# CC2753 register map
File version: 1.0
CPU: CM0+ r0p4, little endian, no MPU, no FPU, VTOR, 3 interrupt priority bits
Registers are 32-bit, read-write, reset 0x0 unless marked. A register's access mark holds for its fields unless they carry their own. Offsets are from the block's base; [hi:lo] are bit positions; {n}, {i} and the like mark numbered series.

## UART0 — Universal Asynchronous Receiver/Transmitter (UART) interface
Base 0x40034000
Same registers: UART1 0x40035000
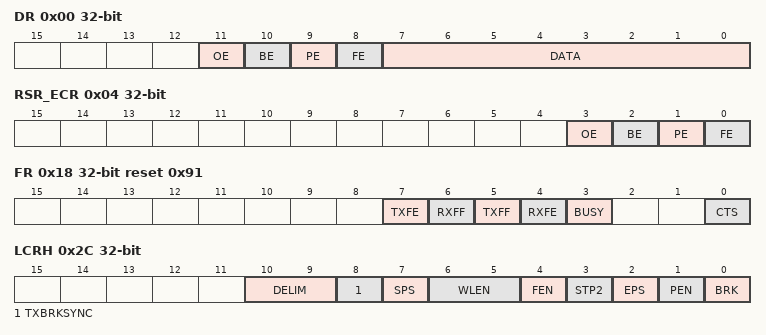
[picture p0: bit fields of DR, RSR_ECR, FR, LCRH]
0x00 DR — Data For words to be transmitted: - if the FIFOs are enabled (LCRH.FEN = 1), data written to this location is pushed onto the transmit FIFO - if the FIFOs are not enabled (LCRH.FEN = 0), data is stored in the transmitter holding register (the bottom word of the transmit FIFO). The write operation initiates transmission from the UART. The data is prefixed with a start bit, appended with the appropriate parity bit (if parity is enabled), and a stop bit. The resultant word is then transmitted. For received words: - if the FIFOs are enabled (LCRH.FEN = 1), the data byte and the 4-bit status (break, frame, parity, and overrun) is pushed onto the 12-bit wide receive FIFO - if the FIFOs are not enabled (LCRH.FEN = 0), the data byte and status are stored in the receiving holding register (the bottom word of the receive FIFO). The received data byte is read by performing reads from this register along with the corresponding status information. The status information can also be read by a read of the RSR_ECR register.
  [11] OE ro — UART Overrun Error: This bit is set to 1 if data is received and the receive FIFO is already full. The FIFO contents remain valid because no more data is written when the FIFO is full, only the contents of the shift register are overwritten. This is cleared to 0 once there is an empty space in the FIFO and a new character can be written to it.
  [10] BE ro — UART Break Error: This bit is set to 1 if a break condition was detected, indicating that the received data input (UARTRXD input pin) was held LOW for longer than a full-word transmission time (defined as start, data, parity and stop bits). In FIFO mode, this error is associated with the character at the top of the FIFO (i.e., the oldest received data character since last read). When a break occurs, a 0 character is loaded into the FIFO. The next character is enabled after the receive data input (UARTRXD input pin) goes to a 1 (marking state), and the next valid start bit is received.
  [9] PE ro — UART Parity Error: When set to 1, it indicates that the parity of the received data character does not match the parity that the LCRH.EPS and LCRH.SPS select. In FIFO mode, this error is associated with the character at the top of the FIFO (i.e., the oldest received data character since last read).
  [8] FE ro — UART Framing Error: When set to 1, it indicates that the received character did not have a valid stop bit (a valid stop bit is 1). In FIFO mode, this error is associated with the character at the top of the FIFO (i.e., the oldest received data character since last read).
  [7:0] DATA — Data transmitted or received: On writes, the transmit data character is pushed into the FIFO. On reads, the oldest received data character since the last read is returned.
0x04 RSR_ECR — Status This register is mapped to the same address as ECR register. Reads from this address are associated with RSR_ECR register and return the receive status. Writes to this address are associated with ECR register and clear the receive status flags (framing, parity, break, and overrun errors). If the status is read from this register, then the status information for break, framing and parity corresponds to the data character read from the Data Register DR, prior to reading the RSR_ECR. The status information for overrun is set immediately when an overrun condition occurs.
  [all] fields
    1=CLEAR_ERROR_1 (Clears error flag if error is set. Write value is not important.); 0=ERROR_NOTSET (Error flag is not set)
  [3] OE — UART Overrun Error: This bit is set to 1 if data is received and the receive FIFO is already full. The FIFO contents remain valid because no more data is written when the FIFO is full, only the contents of the shift register are overwritten. This is cleared to 0 once there is an empty space in the FIFO and a new character can be written to it.
  [2] BE — UART Break Error: This bit is set to 1 if a break condition was detected, indicating that the received data input (UARTRXD input pin) was held LOW for longer than a full-word transmission time (defined as start, data, parity and stop bits). When a break occurs, a 0 character is loaded into the FIFO. The next character is enabled after the receive data input (UARTRXD input pin) goes to a 1 (marking state), and the next valid start bit is received.
  [1] PE — UART Parity Error: When set to 1, it indicates that the parity of the received data character does not match the parity that the LCRH.EPS and LCRH.SPS select.
  [0] FE — UART Framing Error: When set to 1, it indicates that the received character did not have a valid stop bit (a valid stop bit is 1).
0x18 FR ro reset 0x91 — Flag Reads from this register return the UART flags.
  [7] TXFE — UART Transmit FIFO Empty: The meaning of this bit depends on the state of LCRH.FEN . - If the FIFO is disabled, this bit is set when the transmit holding register is empty. - If the FIFO is enabled, this bit is set when the transmit FIFO is empty. This bit does not indicate if there is data in the transmit shift register.
  [6] RXFF — UART Receive FIFO Full: The meaning of this bit depends on the state of LCRH.FEN. - If the FIFO is disabled, this bit is set when the receive holding register is full. - If the FIFO is enabled, this bit is set when the receive FIFO is full.
  [5] TXFF — UART Transmit FIFO Full: Transmit FIFO full. The meaning of this bit depends on the state of LCRH.FEN. - If the FIFO is disabled, this bit is set when the transmit holding register is full. - If the FIFO is enabled, this bit is set when the transmit FIFO is full.
  [4] RXFE — UART Receive FIFO Empty: Receive FIFO empty. The meaning of this bit depends on the state of LCRH.FEN. - If the FIFO is disabled, this bit is set when the receive holding register is empty. - If the FIFO is enabled, this bit is set when the receive FIFO is empty.
  [3] BUSY — UART Busy: If this bit is set to 1, the UART is busy transmitting data. This bit remains set until the complete byte, including all the stop bits, has been sent from the shift register. This bit is set as soon as the transmit FIFO becomes non-empty, regardless of whether the UART is enabled or not.
  [0] CTS — Clear To Send: This bit is the complement of the active-low UART CTS input pin. That is, the bit is 1 when CTS input pin is LOW.
0x20 UARTILPR — IrDA Low-Power Counter Register. This is an 8-bit register that stores the low-power counter divisor value used to generate the IrLPBaud16 signal by dividing down of UARTCLK.
  [7:0] ILPDVSR — 8 bit low-power divisor value. In low-power IrDA mode the UART rejects random noise on the received serial data input by ignoring SIRIN pulses that are less than 3 periods of IrLPBaud16.
0x24 IBRD — Integer Baud-Rate Divisor If this register is modified while trasmission or reception is on-going, the baudrate will not be updated until transmission or reception of the current character is complete.
  [15:0] DIVINT — The integer baud rate divisor: The baud rate divisor is calculated using the formula below: Baud rate divisor = (UART reference clock frequency) / (16 * Baud rate) Baud rate divisor must be minimum 1 and maximum 65535. That is, DIVINT=0 does not give a valid baud rate. Similarly, if DIVINT=0xFFFF, any non-zero values in FBRD.DIVFRAC will be illegal. A valid value must be written to this field before the UART can be used for RX or TX operations.
0x28 FBRD — Fractional Baud-Rate Divisor If this register is modified while trasmission or reception is on-going, the baudrate will not be updated until transmission or reception of the current character is complete.
  [5:0] DIVFRAC — Fractional Baud-Rate Divisor: The baud rate divisor is calculated using the formula below: Baud rate divisor = (UART reference clock frequency) / (16 * Baud rate) Baud rate divisor must be minimum 1 and maximum 65535. That is, IBRD.DIVINT=0 does not give a valid baud rate. Similarly, if IBRD.DIVINT=0xFFFF, any non-zero values in DIVFRAC will be illegal. A valid value must be written to this field before the UART can be used for RX or TX operations.
0x2C LCRH — Line Control
  [10:9] DELIM — In UART LIN defines the length of DELIM field that has to be sent
    {v}=LEN_{v+1} (v=0..3)
  [8] TXBRKSYNC — UART LIN mode TXBRKSYNC: 0: In LIN mode TXBRKSYNC will not be sent. 1: In LIN mode send TXBRKSYNC field and reset the LCRH.TXBRKSYNC bit. This bit has no effect when PEN disables parity checking and generation.
  [7] SPS — UART Stick Parity Select: 0: Stick parity is disabled 1: The parity bit is transmitted and checked as invert of EPS field (i.e. the parity bit is transmitted and checked as 1 when EPS = 0). This bit has no effect when PEN disables parity checking and generation.
  [6:5] WLEN — UART Word Length: These bits indicate the number of data bits transmitted or received in a frame.
    {v}=BITL{v+5} (Word Length {v+5} bits) (v=0..3)
  [4] FEN — UART Enable FIFOs
    1=EN (Transmit and receive FIFO buffers are enabled (FIFO mode)); 0=DIS (FIFOs are disabled (character mode) that is, the FIFOs become 1-byte-deep holding registers.)
  [3] STP2 — UART Two Stop Bits Select: If this bit is set to 1, two stop bits are transmitted at the end of the frame. The receive logic does not check for two stop bits being received.
  [2] EPS — UART Even Parity Select
    1=EVEN (Even parity: The UART generates or checks for an even number of 1s in the data and parity bits.); 0=ODD (Odd parity: The UART generates or checks for an odd number of 1s in the data and parity bits.)
  [1] PEN — UART Parity Enable This bit controls generation and checking of parity bit.
    1=EN (Parity checking and generation is enabled.); 0=DIS (Parity is disabled and no parity bit is added to the data frame)
  [0] BRK — UART Send Break If this bit is set to 1, a low-level is continually output on the UARTTXD output pin, after completing transmission of the current character. For the proper execution of the break command, the software must set this bit for at least two complete frames. For normal use, this bit must be cleared to 0.
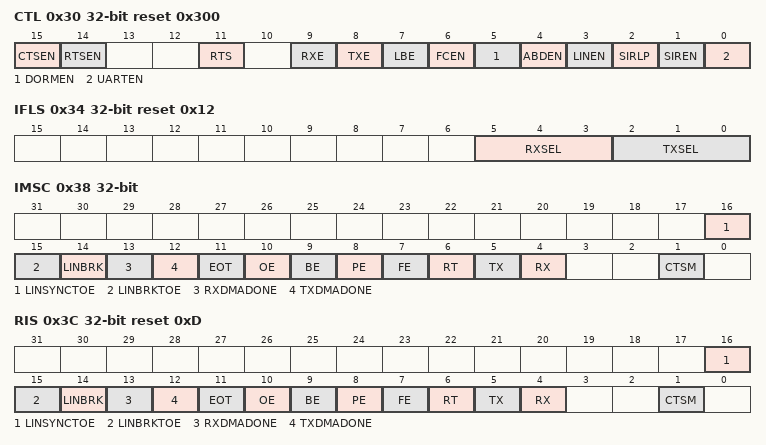
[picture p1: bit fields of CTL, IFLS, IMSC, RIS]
0x30 CTL reset 0x300 — Control
  [15] CTSEN — CTS hardware flow control enable
    1=EN (CTS hardware flow control enabled); 0=DIS (CTS hardware flow control disabled)
  [14] RTSEN — RTS hardware flow control enable
    1=EN (RTS hardware flow control enabled); 0=DIS (RTS hardware flow control disabled)
  [11] RTS — Request to Send This bit is the complement of the active-low UART RTS output. That is, when the bit is programmed to a 1 then RTS output on the pins is LOW.
  [9] RXE — UART Receive Enable If the UART is disabled in the middle of reception, it completes the current character before stopping.
    1=EN (UART Receive enabled); 0=DIS (UART Receive disabled)
  [8] TXE — UART Transmit Enable If the UART is disabled in the middle of transmission, it completes the current character before stopping.
    1=EN (UART Transmit enabled); 0=DIS (UART Transmit disabled)
  [7] LBE — UART Loop Back Enable Enabling the loop-back mode connects the UARTTXD output from the UART to UARTRXD input of the UART.
    1=EN (Loop Back enabled); 0=DIS (Loop Back disabled)
  [6] FCEN — UART FIFO Concatenation Enable Enabling the FIFO concatenation in TX mode resulting in 16 TX buffers.
    1=EN (UART FIFO Concatenation enabled); 0=DIS (UART FIFO Concatenation disabled)
  [5] DORMEN — DORMEN bit is only functionally makes sense for LIN mode of operation. When dormant mode is disabled, break and synch data shall be loaded to RX FIFO and associated interrupt flags shall be set as in normal UART operation. When dormant mode is enabled, break and synch data shall not be loaded to RX FIFO and RX FIFO shall be updated with actual data (PID) only after successful reception of break/synch fields.
    1=EN; 0=DIS
  [4] ABDEN — This configuration bit defines whether we want automatic baud rate detection enabled or not in the LIN mode of operation.
    1=EN; 0=DIS
  [3] LINEN — This is the LIN Mode of operation configuration bit.
    1=EN; 0=DIS
  [2] SIRLP — SIR low power IrDA mode This bit selects the IrDA encoding mode
    1=EN (Low-level bits are transmitted with a pulse width of 3 times the period of IrLPBaud16(which has a frequency of (UARTCLK frequency)/UARTILP.ILPDVSR), regardless of the selected bit rate. In low-power IrDA mode the UART rejects random noise on the received serial data input by ignoring SIRIN pulses that are less than 3 periods of IrLPBaud16.); 0=DIS (Low-level bits are transmitted as active high with a 3/16th period width,)
  [1] SIREN — SIR Enable This bit has no effect if UARTEN bit disables the UART.
    1=EN (IrDA SIR ENDEC is enabled. Data is transmitted and received via nSIROUT and SIRIN.); 0=DIS (IrDA SIR ENDEC is disabled)
  [0] UARTEN — UART Enable
    1=EN (UART enabled); 0=DIS (UART disabled)
0x34 IFLS reset 0x12 — Interrupt FIFO Level Select
  [5:3] RXSEL — Receive interrupt FIFO level select: This field sets the trigger points for the receive interrupt. Values 0b101-0b111 are reserved.
    3=THREEQU (Receive FIFO becomes $gt;= 3/4 full); 2=HALF (Receive FIFO becomes $gt;= 1/2 full); 1=QUARTER (Receive FIFO becomes $gt;= 1/4 full)
  [2:0] TXSEL — Transmit interrupt FIFO level select: This field sets the trigger points for the transmit interrupt. Values 0b101-0b111 are reserved.
    3=THREEQU (Transmit FIFO becomes $lt;= 3/4 full); 2=HALF (Transmit FIFO becomes $lt;= 1/2 full); 1=QUARTER (Transmit FIFO becomes $lt;= 1/4 full)
0x38 IMSC — Interrupt Mask Set/Clear
  [16] LINSYNCTOE — LIN Sync Time out error interrupt mask. A read returns the current mask for UART's LINSYNCTOE interrupt. On a write of 1, the mask of the LINSYNCTOE interrupt is set which means the interrupt state will be reflected in MIS.LINSYNCTOE. A write of 0 clears the mask which means MIS.LINSYNCTOE will not reflect the interrupt.
  [15] LINBRKTOE — LIN Break field Time out error interrupt mask. A read returns the current mask for UART's LINBRKTOE interrupt. On a write of 1, the mask of the LINBRKTOE interrupt is set which means the interrupt state will be reflected in MIS.LINBRKTOE. A write of 0 clears the mask which means MIS.LINBRKTOE will not reflect the interrupt.
  [14] LINBRK — LIN Break field recieved/detected interrupt mask. A read returns the current mask for UART's LINBRK interrupt. On a write of 1, the mask of the LINBRK interrupt is set which means the interrupt state will be reflected in MIS.LINBRK. A write of 0 clears the mask which means MIS.LINBRK will not reflect the interrupt.
  [13] RXDMADONE — RX DMA done interrupt mask. A read returns the current mask for UART's RXDMADONE interrupt. On a write of 1, the mask of the RXDMADONE interrupt is set which means the interrupt state will be reflected in MIS.RXDMADONE. A write of 0 clears the mask which means MIS.RXDMADONE will not reflect the interrupt.
  [12] TXDMADONE — TX DMA done interrupt mask. A read returns the current mask for UART's TXDMADONE interrupt. On a write of 1, the mask of the TXDMADONE interrupt is set which means the interrupt state will be reflected in MIS.TXDMADONE. A write of 0 clears the mask which means MIS.TXDMADONE will not reflect the interrupt.
  [11] EOT — End of Transmission interrupt mask. A read returns the current mask for UART's EoT interrupt. On a write of 1, the mask of the EoT interrupt is set which means the interrupt state will be reflected in MIS.EOT. A write of 0 clears the mask which means MIS.EOT will not reflect the interrupt.
  [10] OE — Overrun error interrupt mask. A read returns the current mask for UART's overrun error interrupt. On a write of 1, the mask of the overrun error interrupt is set which means the interrupt state will be reflected in MIS.OE. A write of 0 clears the mask which means MIS.OE will not reflect the interrupt.
  [9] BE — Break error interrupt mask. A read returns the current mask for UART's break error interrupt. On a write of 1, the mask of the overrun error interrupt is set which means the interrupt state will be reflected in MIS.BE. A write of 0 clears the mask which means MIS.BE will not reflect the interrupt.
  [8] PE — Parity error interrupt mask. A read returns the current mask for UART's parity error interrupt. On a write of 1, the mask of the overrun error interrupt is set which means the interrupt state will be reflected in MIS.PE. A write of 0 clears the mask which means MIS.PE will not reflect the interrupt.
  [7] FE — Framing error interrupt mask. A read returns the current mask for UART's framing error interrupt. On a write of 1, the mask of the overrun error interrupt is set which means the interrupt state will be reflected in MIS.FE. A write of 0 clears the mask which means MIS.FE will not reflect the interrupt.
  [6] RT — Receive timeout interrupt mask. A read returns the current mask for UART's receive timeout interrupt. On a write of 1, the mask of the overrun error interrupt is set which means the interrupt state will be reflected in MIS.RT. A write of 0 clears the mask which means this bitfield will not reflect the interrupt. The raw interrupt for receive timeout RIS.RT cannot be set unless the mask is set (RT = 1). This is because the mask acts as an enable for power saving. That is, the same status can be read from MIS.RT and RIS.RT.
  [5] TX — Transmit interrupt mask. A read returns the current mask for UART's transmit interrupt. On a write of 1, the mask of the overrun error interrupt is set which means the interrupt state will be reflected in MIS.TX. A write of 0 clears the mask which means MIS.TX will not reflect the interrupt.
  [4] RX — Receive interrupt mask. A read returns the current mask for UART's receive interrupt. On a write of 1, the mask of the overrun error interrupt is set which means the interrupt state will be reflected in MIS.RX. A write of 0 clears the mask which means MIS.RX will not reflect the interrupt.
  [1] CTSM — Clear to Send (CTS) modem interrupt mask. A read returns the current mask for UART's clear to send interrupt. On a write of 1, the mask of the overrun error interrupt is set which means the interrupt state will be reflected in MIS.CTSM. A write of 0 clears the mask which means MIS.CTSM will not reflect the interrupt.
0x3C RIS ro reset 0xD — Raw Interrupt Status
  [16] LINSYNCTOE — LIN SYNC field time out interrupt status: This field returns the raw interrupt state of whether sync field is measurable in UART's LIN mode of operation. This is set when the timer measuring the SYNC field overflows.
  [15] LINBRKTOE — LIN BRK field time out interrupt status: This field returns the raw interrupt state of whether break field is measurable in UART's LIN mode of operation. This is set when the timer measuring the Break field overflows.
  [14] LINBRK — LIN BRK detected interrupt status: This field returns the raw interrupt state of whether break field is recieved/detected in UART's LIN mode of operation.
  [13] RXDMADONE — RX DMA done interrupt status: This field returns the raw interrupt state of UART's RX DMA done interrupt. RX DMA done flag is set when you recieve RX DMA done status from dma module.
  [12] TXDMADONE — TX DMA done interrupt status: This field returns the raw interrupt state of UART's TX DMA done interrupt. TX DMA done flag is set when you recieve TX DMA done status from dma module.
  [11] EOT — End of Transmission interrupt status: This field returns the raw interrupt state of UART's end of transmission interrupt. End of transmission flag is set when all the Transmit data in the FIFO and on the TX Line is tranmitted.
  [10] OE — Overrun error interrupt status: This field returns the raw interrupt state of UART's overrun error interrupt. Overrun error occurs if data is received and the receive FIFO is full.
  [9] BE — Break error interrupt status: This field returns the raw interrupt state of UART's break error interrupt. Break error is set when a break condition is detected, indicating that the received data input (UARTRXD input pin) was held LOW for longer than a full-word transmission time (defined as start, data, parity and stop bits).
  [8] PE — Parity error interrupt status: This field returns the raw interrupt state of UART's parity error interrupt. Parity error is set if the parity of the received data character does not match the parity that the LCRH.EPS and LCRH.SPS select.
  [7] FE — Framing error interrupt status: This field returns the raw interrupt state of UART's framing error interrupt. Framing error is set if the received character does not have a valid stop bit (a valid stop bit is 1).
  [6] RT — Receive timeout interrupt status: This field returns the raw interrupt state of UART's receive timeout interrupt. The receive timeout interrupt is asserted when the receive FIFO is not empty, and no more data is received during a 32-bit period. The receive timeout interrupt is cleared either when the FIFO becomes empty through reading all the data, or when a 1 is written to ICR.RT. The raw interrupt for receive timeout cannot be set unless the mask is set (IMSC.RT = 1). This is because the mask acts as an enable for power saving. That is, the same status can be read from MIS.RT and RT.
  [5] TX — Transmit interrupt status: This field returns the raw interrupt state of UART's transmit interrupt. When FIFOs are enabled (LCRH.FEN = 1), the transmit interrupt is asserted if the number of bytes in transmit FIFO is equal to or lower than the programmed trigger level (IFLS.TXSEL). The transmit interrupt is cleared by writing data to the transmit FIFO until it becomes greater than the trigger level, or by clearing the interrupt through ICR.TX. When FIFOs are disabled (LCRH.FEN = 0), that is they have a depth of one location, the transmit interrupt is asserted if there is no data present in the transmitters single location. It is cleared by performing a single write to the transmit FIFO, or by clearing the interrupt through ICR.TX.
  [4] RX — Receive interrupt status: This field returns the raw interrupt state of UART's receive interrupt. When FIFOs are enabled (LCRH.FEN = 1), the receive interrupt is asserted if the receive FIFO reaches the programmed trigger level (IFLS.RXSEL). The receive interrupt is cleared by reading data from the receive FIFO until it becomes less than the trigger level, or by clearing the interrupt through ICR.RX. When FIFOs are disabled (LCRH.FEN = 0), that is they have a depth of one location, the receive interrupt is asserted if data is received thereby filling the location. The receive interrupt is cleared by performing a single read of the receive FIFO, or by clearing the interrupt through ICR.RX.
  [1] CTSM — Clear to Send (CTS) modem interrupt status: This field returns the raw interrupt state of UART's clear to send interrupt.
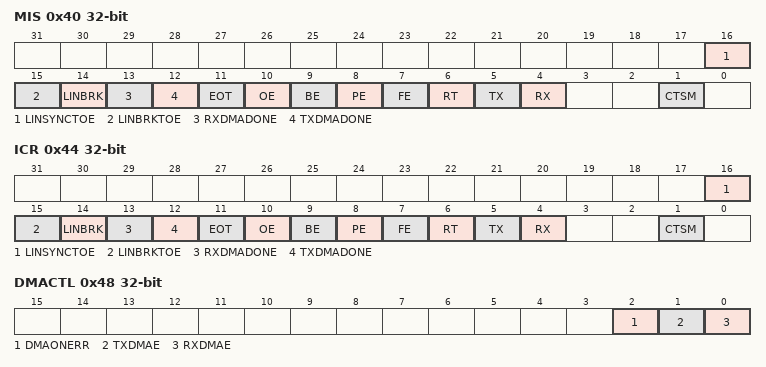
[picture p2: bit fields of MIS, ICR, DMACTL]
0x40 MIS ro — Masked Interrupt Status
  [16] LINSYNCTOE — LIN sync field time out error interrupt status: This field returns the masked interrupt state of the LIN sync timeout error interrupt which is the AND product of raw interrupt state RIS.LINSYNCTOERIS and the mask setting IMSC.LINSYNCTOEIM.
  [15] LINBRKTOE — LIN BRK field time out error interrupt status: This field returns the masked interrupt state of the LIN BRK timeout error interrupt which is the AND product of raw interrupt state RIS.LINBRKTOERIS and the mask setting IMSC.LINBRKTOEIM.
  [14] LINBRK — LIN BRK field detected interrupt status: This field returns the masked interrupt state of the LIN BRK detected interrupt which is the AND product of raw interrupt state RIS.LINBRKRIS and the mask setting IMSC.LINBRKIM.
  [13] RXDMADONE — RX DMA done interrupt status: This field returns the masked interrupt state of the RX DMA done interrupt which is the bitiwse AND product of raw interrupt state RIS.RXDMADONE and the mask setting IMSC.RXDMADONE.
  [12] TXDMADONE — TX DMA done interrupt status: This field returns the masked interrupt state of the TX DMA done interrupt which is the bitwise AND product of raw interrupt state RIS.TXDMADONE and the mask setting IMSC.TXDMADONE.
  [11] EOT — End of Transmission interrupt status: This field returns the masked interrupt state of the End of transmission interrupt which is the bitwise AND product of raw interrupt state RIS.EOT and the mask setting IMSC.EOT.
  [10] OE — Overrun error masked interrupt status: This field returns the masked interrupt state of the overrun interrupt which is the bitwise AND product of raw interrupt state RIS.OE and the mask setting IMSC.OE.
  [9] BE — Break error masked interrupt status: This field returns the masked interrupt state of the break error interrupt which is the bitiwse AND product of raw interrupt state RIS.BE and the mask setting IMSC.BE.
  [8] PE — Parity error masked interrupt status: This field returns the masked interrupt state of the parity error interrupt which is the bitiwise AND product of raw interrupt state RIS.PE and the mask setting IMSC.PE.
  [7] FE — Framing error masked interrupt status: Returns the masked interrupt state of the framing error interrupt which is the bitiwse AND product of raw interrupt state RIS.FE and the mask setting IMSC.FE.
  [6] RT — Receive timeout masked interrupt status: Returns the masked interrupt state of the receive timeout interrupt. The raw interrupt for receive timeout cannot be set unless the mask is set (IMSC.RT = 1). This is because the mask acts as an enable for power saving. That is, the same status can be read from MIS.RT and RIS.RT.
  [5] TX — Transmit masked interrupt status: This field returns the masked interrupt state of the transmit interrupt which is the bitiwse AND product of raw interrupt state RIS.TX and the mask setting IMSC.TX.
  [4] RX — Receive masked interrupt status: This field returns the masked interrupt state of the receive interrupt which is the bitwise AND product of raw interrupt state RIS.RX and the mask setting IMSC.RX.
  [1] CTSM — Clear to Send (CTS) modem masked interrupt status: This field returns the masked interrupt state of the clear to send interrupt which is the bitwise AND product of raw interrupt state RIS.CTS and the mask setting IMSC.CTS.
0x44 ICR wo — Interrupt Clear On a write of 1, the corresponding interrupt is cleared. A write of 0 has no effect.
  [16] LINSYNCTOE — LIN SYNC timeout interrupt clear: Writing 1 to this field clears the rxdma done interrupt (RIS.LINSYNCTOE). Writing 0 has no effect.
  [15] LINBRKTOE — LIN BRK field timeout interrupt clear: Writing 1 to this field clears the rxdma done interrupt (RIS.LINBRKTOE). Writing 0 has no effect.
  [14] LINBRK — LIN BRK field detected interrupt clear: Writing 1 to this field clears the rxdma done interrupt (RIS.LINBRK). Writing 0 has no effect.
  [13] RXDMADONE — RX DMA Done interrupt clear: Writing 1 to this field clears the RX DMA done interrupt (RIS.RXDMADONE). Writing 0 has no effect.
  [12] TXDMADONE — TX DMA Done interrupt clear: Writing 1 to this field clears the TX DMA done interrupt (RIS.TXDMADONE). Writing 0 has no effect.
  [11] EOT — End of Transmission interrupt clear: Writing 1 to this field clears the End of Transmission interrupt (RIS.EOT). Writing 0 has no effect.
  [10] OE — Overrun error interrupt clear: Writing 1 to this field clears the overrun error interrupt (RIS.OE). Writing 0 has no effect.
  [9] BE — Break error interrupt clear: Writing 1 to this field clears the break error interrupt (RIS.BE). Writing 0 has no effect.
  [8] PE — Parity error interrupt clear: Writing 1 to this field clears the parity error interrupt (RIS.PE). Writing 0 has no effect.
  [7] FE — Framing error interrupt clear: Writing 1 to this field clears the framing error interrupt (RIS.FE). Writing 0 has no effect.
  [6] RT — Receive timeout interrupt clear: Writing 1 to this field clears the receive timeout interrupt (RIS.RT). Writing 0 has no effect.
  [5] TX — Transmit interrupt clear: Writing 1 to this field clears the transmit interrupt (RIS.TX). Writing 0 has no effect.
  [4] RX — Receive interrupt clear: Writing 1 to this field clears the receive interrupt (RIS.RX). Writing 0 has no effect.
  [1] CTSM — Clear to Send (CTS) modem interrupt clear: Writing 1 to this field clears the clear to send interrupt (RIS.CTS). Writing 0 has no effect.
0x48 DMACTL — DMA Control
  [2] DMAONERR — DMA on error. If this bit is set to 1, the DMA receive request outputs (for single and burst requests) are disabled when the UART error interrupt is asserted (more specifically if any of the error interrupts RIS.PERIS, RIS.BERIS, RIS.FERIS or RIS.OERIS are asserted).
  [1] TXDMAE — Transmit DMA enable. If this bit is set to 1, DMA for the transmit FIFO is enabled.
  [0] RXDMAE — Receive DMA enable. If this bit is set to 1, DMA for the receive FIFO is enabled.
